# RL7005_IP_SVD register map
Vendor: Realtek
Registers are 32-bit, read-write, reset 0x0 unless marked. A register's access mark holds for its fields unless they carry their own. Offsets are from the block's base; [hi:lo] are bit positions.

## SDIO_WIFI_REG
Base 0x40111000
0xA0 SPDIO_TXBD_ADDR
  [31:0] SPDIO_TXFIFO_ADDR — The base address of TXBD The value of this register should be configure by CPU It should be 4 byte alignment (Because TXBD Size is 8 Byte).
0xA4 SPDIO_TXBD_NUM
  [15:0] SPDIO_TXBD_NUM — The Number of TXBD. Unit: Number The value of this register should be configured by CPU
0xA8 SPDIO_TXBD_WPTR ro
  [15:0] SPDIO_TXBD_H2C_WPTR — When the packet has been sent from Host to TX Buffer, this index should be updated by SDIO IP.
0xAC SPDIO_TXBD_RPTR
  [15:0] SPDIO_TXBD_H2C_RPTR — When the packet has been processed by CPU and moved to MAC TX FIFO, this index should be updated by CPU.
0xB0 SPDIO_RXBD_ADDR
  [31:0] SPDIO_RXBD_ADDR — The base address of RX BD. The value of this register should be configured by CPU. It should be 8-Byte alignment
0xB4 SPDIO_RXBD_NUM 16-bit
  [15:0] SPDIO_RXBD_NUM — The total count of RX BD The value of this register should be configured by CPU. The unit is BD count
0xB6 SPDIO_RXBD_C2H_WPTR 16-bit
  [15:0] SPDIO_RXBD_C2H_WPTR — When the packet has been processed by CPU and to be moved to host, this index should be updated by CPU
0xB8 SPDIO_RXBD_C2H_RPTR 16-bit ro
  [15:0] SPDIO_RXBD_C2H_RPTR — When the packet has been moved to host, this index should be updated by SDIO IP.
0xBA SPDIO_HCI_RX_REQ 8-bit
  [0] HCI_RX_REQ — CPU triggers this bit to enable SDIO IP RX transfer by fetch BD info. SDIO fetch BD to get the RX length and address and transfer RX packet to Host, and clear this bit when all BD transfer done.
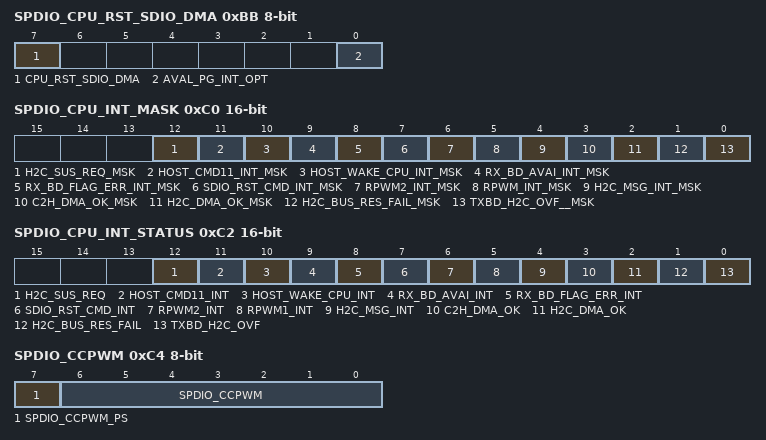
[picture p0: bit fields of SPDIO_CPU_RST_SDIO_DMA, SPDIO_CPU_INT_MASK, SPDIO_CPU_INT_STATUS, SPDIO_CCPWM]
0xBB SPDIO_CPU_RST_SDIO_DMA 8-bit
  [7] CPU_RST_SDIO_DMA — CPU set this bit to reset SDIO DMA. This bit is auto clear.
  [0] AVAL_PG_INT_OPT — set 1 to disable clearing tx_aval_pg_int by read tx_aval_pg_num
0xBC SPDIO_RX_REQ_ADDR ro
  [31:0] SPDIO_RX_REQ_ADDR — The address of the requested RX Packet. This is unnecessary for driver.
0xC0 SPDIO_CPU_INT_MASK 16-bit
  [12] H2C_SUS_REQ_MSK — This bit is clear, and H2C_SUS_REQ is masked
  [11] HOST_CMD11_INT_MSK — This bit is clear, and HOST_CMD11_INT is masked
  [10] HOST_WAKE_CPU_INT_MSK — This bit is clear, and HOST_WAKE_CPU_INT is masked
  [9] RX_BD_AVAI_INT_MSK — This bit is clear, and RX_BD_AVAI_INT is masked
  [8] RX_BD_FLAG_ERR_INT_MSK — This bit is clear, and RX_BD_FLAG_ERR_INT is masked
  [7] SDIO_RST_CMD_INT_MSK — This bit is clear, and SDIO_RST_CMD_INT is masked
  [6] RPWM2_INT_MSK — This bit is clear, and RPWM2_INT is masked
  [5] RPWM_INT_MSK — This bit is clear, and RPWM_INT is masked
  [4] H2C_MSG_INT_MSK — This bit is clear, and H2C_MSG_INT is masked
  [3] C2H_DMA_OK_MSK — This bit is clear, and C2H_DMA_OK _INT is masked
  [2] H2C_DMA_OK_MSK — This bit is clear, and H2C_DMA_OK _INT is masked
  [1] H2C_BUS_RES_FAIL_MSK — This bit is clear, and H2C_BUS_RES_FAIL_INT is masked
  [0] TXBD_H2C_OVF__MSK — This bit is clear, and TXBD_H2C_OVF is masked
0xC2 SPDIO_CPU_INT_STATUS 16-bit
  [12] H2C_SUS_REQ — Host write sdio local reg to trigger suspend request interrupt
  [11] HOST_CMD11_INT — When Host sends CMD11 to notify that the signal voltage level is going to switch to 1.8v, the HW should issue this interrupt to notify the local CPU to do the LDO power voltage level switch.
  [10] HOST_WAKE_CPU_INT — When Host Send TRX CMD53 while CPU is not ready (SYSTEM_CPU_RDY_IND=0, or CPU_RDY_IND=0), trigger this interrupt to wake CPU, and then indicate BUSY status to host. CPU should be able to receive this interrupt even CPU clock is gated; therefore, this interrupt should be connected to System On circuit.
  [9] RX_BD_AVAI_INT — If the free RXBD Number become larger than FREE_RXBD_COUNT(0x1D8), trigger this interrupt. This interrupt trigger only once when free RXBD number cross FREE_RXBD_COUNT
  [8] RX_BD_FLAG_ERR_INT — Trigger by SDIO to CPU when detect RX_BD error
  [7] SDIO_RST_CMD_INT — Trigger by SDIO to CPU when SDIO is reset. CPU should be able to receive this interrupt even CPU clock is gated; therefore, this interrupt should be connected to System On circuit.
  [6] RPWM2_INT — Trigger by SDIO to CPU that RPWM2 occurs (HRPWM2 is toggled) CPU should be able to receive this interrupt even CPU clock is gated; therefore, this interrupt should be connected to System On circuit.
  [5] RPWM1_INT — Trigger by SDIO to CPU that RPWM1 occurs(HRPWM1 is toggled) CPU should be able to receive this interrupt even CPU clock is gated; therefore, this interrupt should be connected to System On circuit.
  [4] H2C_MSG_INT — Trigger by SDIO to CPU that H2C_MSG_INT occurs(REG_SDIO_H2C_MSG is toggled)
  [3] C2H_DMA_OK — Trigger by SDIO to CPU that packet is sent from RXFIFO to Host
  [2] H2C_DMA_OK — Trigger by SDIO to CPU that packet is sent from Host to TXFIFO
  [1] H2C_BUS_RES_FAIL — If SDIO is going to move packet to TX FIFO and fails to get bus resource, this interrupt raise. Driver Write 1 clear
  [0] TXBD_H2C_OVF — If there is not enough TX_BD for TX Packet, this bit raise. Driver Write 1 clear
0xC4 SPDIO_CCPWM 8-bit
  [7] SPDIO_CCPWM_PS — device write 1 to trigger interrupt to host
  [6:0] SPDIO_CCPWM — ccpwm
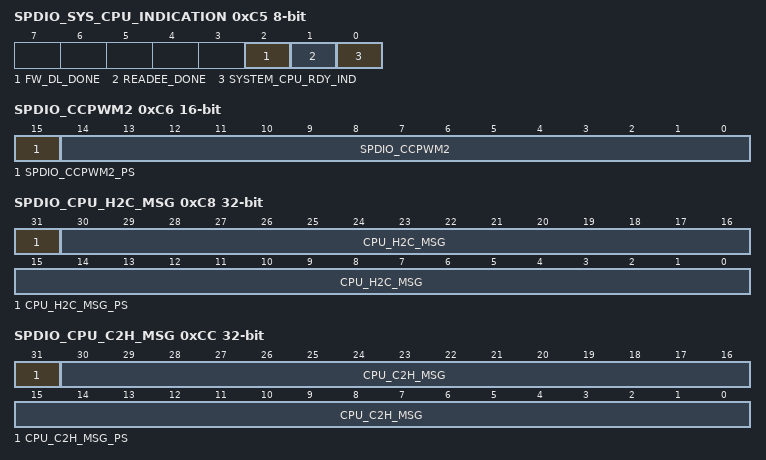
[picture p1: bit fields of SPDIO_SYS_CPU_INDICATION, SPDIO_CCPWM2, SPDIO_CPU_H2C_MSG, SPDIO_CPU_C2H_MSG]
0xC5 SPDIO_SYS_CPU_INDICATION 8-bit access per field
  [2] FW_DL_DONE ro — Host write firmware update done, sync to this bit
  [1] READEE_DONE rw — After cccr reg is configured, write this bit to 1
  [0] SYSTEM_CPU_RDY_IND rw — Used to indicate that CPU is ready for TRX. Default: 0 This bit is synchronized to CPU_RDY_IND(Offset: 0x87)
0xC6 SPDIO_CCPWM2 16-bit
  [15] SPDIO_CCPWM2_PS — device write 1 to trigger interrupt to host
  [14:0] SPDIO_CCPWM2 — ccpwm2
0xC8 SPDIO_CPU_H2C_MSG ro
  [31] CPU_H2C_MSG_PS — host write 1 to trigger interrupt to device
  [30:0] CPU_H2C_MSG — Driver to FW Message
0xCC SPDIO_CPU_C2H_MSG
  [31] CPU_C2H_MSG_PS — device write 1 to trigger interrupt to host
  [30:0] CPU_C2H_MSG — FW to Driver Message
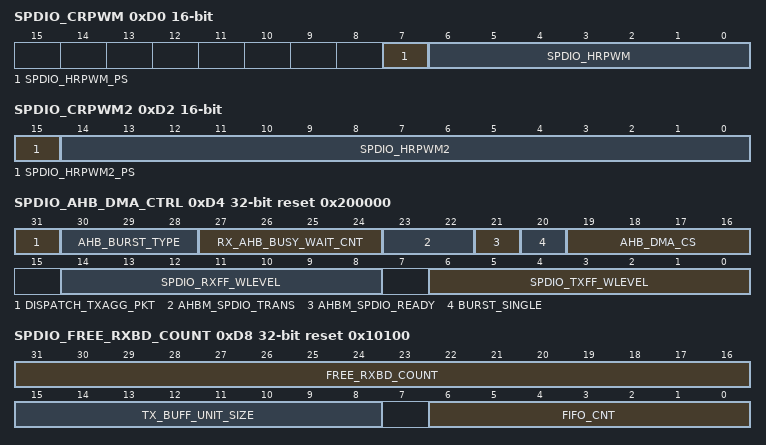
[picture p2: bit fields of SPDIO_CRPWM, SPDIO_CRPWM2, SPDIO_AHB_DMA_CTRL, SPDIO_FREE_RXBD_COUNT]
0xD0 SPDIO_CRPWM 16-bit ro
  [7] SPDIO_HRPWM_PS — host write 1 to trigger interrupt to device
  [6:0] SPDIO_HRPWM — hrpwm
0xD2 SPDIO_CRPWM2 16-bit ro
  [15] SPDIO_HRPWM2_PS — host write 1 to trigger interrupt to device
  [14:0] SPDIO_HRPWM2 — NO USED
0xD4 SPDIO_AHB_DMA_CTRL access per field reset 0x200000
  [31] DISPATCH_TXAGG_PKT rw — Enable SPDIO to dispatch the Aggregated TX packet.
  [30:28] AHB_BURST_TYPE rw — This field is used to control to SPDIO AHB support Burst type. b100: Support Burst 16 DW b010: Support Burst 8 DW b001: Support Burst 4 DW Default is b111, all support.
  [27:24] RX_AHB_BUSY_WAIT_CNT rw — When SPDIO RX transfer, AHB controller will wait BUSY counter for AHB access target not response READY signal. If timeout, AHB controller will issue AHB_BUS_RES_FAIL INT to CPU.
  [23:22] AHBM_SPDIO_TRANS ro — SPDIO AHB Master HTRANS signal
  [21] AHBM_SPDIO_READY ro — SPDIO AHB Master Hready signal
  [20] BURST_SINGLE rw — FORCE AHB Master only to transfer single burst
  [19:16] AHB_DMA_CS ro — AHB DMA state
  [14:8] SPDIO_RXFF_WLEVEL rw — SPDIO FIFO RX water level Range 1~126, it can be modified only when AHB_DMA_CS = 000
  [6:0] SPDIO_TXFF_WLEVEL rw — SPDIO FIFO TX water level Range 1~126, it can be modified only when AHB_DMA_CS = 000
0xD8 SPDIO_FREE_RXBD_COUNT access per field reset 0x10100
  [31:16] FREE_RXBD_COUNT rw — If SPDIO_RXBD_C2H_RPTR is updated and the free RXBD Number is larger than FREE_RXBD_COUNT, trigger RX_BD_AVAI_INT interrupt.
  [15:8] TX_BUFF_UNIT_SIZE rw — The Size of each single TX Buffer which is addressed by TX_BD Unit: 64Byte Ex: 0x01=>64Byte 0x10=>1024Byte
  [6:0] FIFO_CNT ro — The SPDIO Local FIFO counter, for debug usage
0xDC SPDIO_CPU_H2C_MSG_EXT ro
  [31:0] CPU_H2C_MSG_EXT — Driver to FW Message
0xE0 SPDIO_CPU_C2H_MSG_EXT
  [31:0] CPU_C2H_MSG_EXT — FW to driver Message
